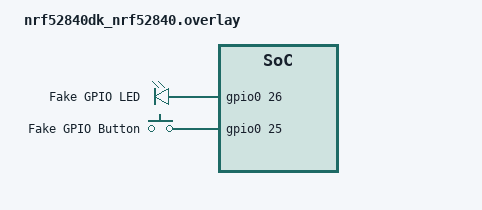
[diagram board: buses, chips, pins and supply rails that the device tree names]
/ {

  aliases {
     svm-button0 = &button100;
     svm-button1 = &button1;
     svm-button2 = &button2;
     svm-button3 = &button3;

     svm-led0 = &led100;
     svm-led1 = &led1;
     svm-led2 = &led2;
     svm-led3 = &led3;

     svm-sys-timer = &timer4;
  };	


   leds {
        compatible = "gpio-leds";
        led100: led_100 {
            gpios = <&gpio0 26 GPIO_ACTIVE_HIGH>;
            label = "Fake GPIO LED";
        };
    };

    buttons {
        compatible = "gpio-keys";
        button100: button_100 {
            gpios = <&gpio0 25 (GPIO_PULL_DOWN | GPIO_ACTIVE_HIGH)>;
            label = "Fake GPIO Button";
        };
    };


};
